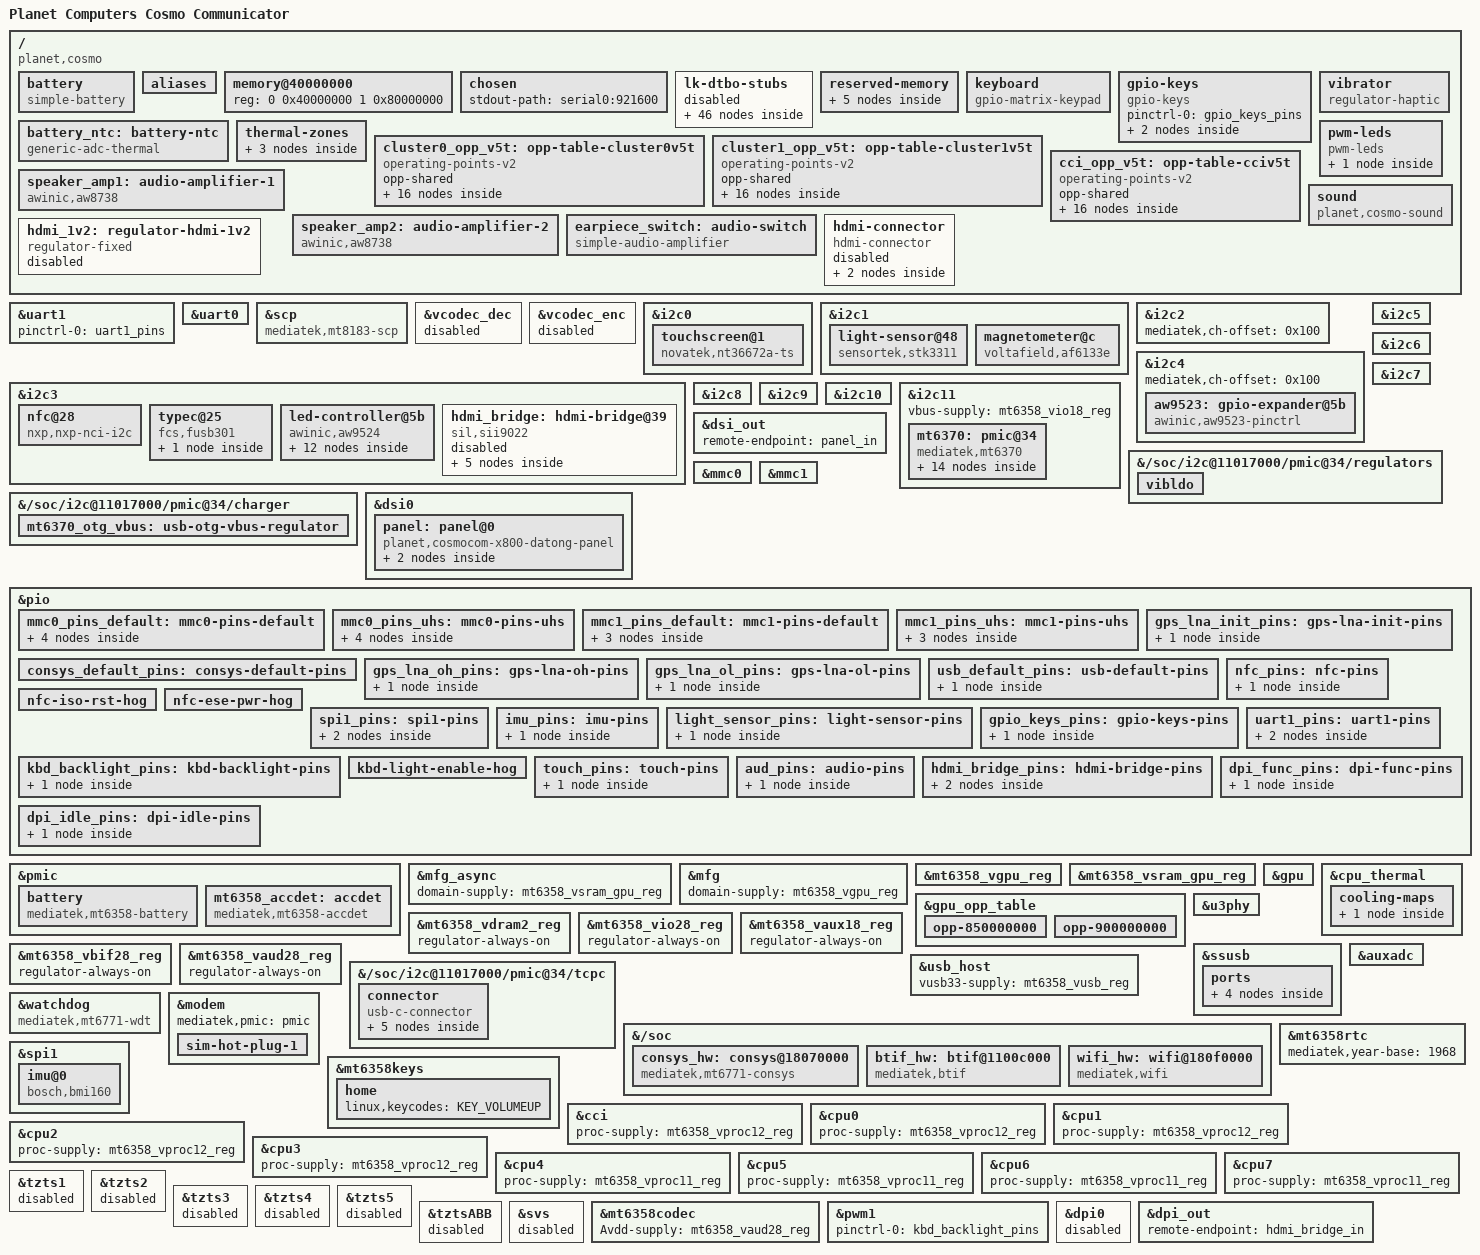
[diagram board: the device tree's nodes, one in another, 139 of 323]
// SPDX-License-Identifier: (GPL-2.0 OR MIT)
/*
 * Planet Computers Cosmo Communicator (board k71v1_64_bsp) on MediaTek MT6771.
 */

/dts-v1/;
#include <dt-bindings/gpio/gpio.h>
#include <dt-bindings/iio/adc/mediatek,mt6370_adc.h>
#include <dt-bindings/input/input.h>
#include <dt-bindings/interrupt-controller/irq.h>
#include <dt-bindings/power/mt8183-power.h>
#include <dt-bindings/clock/mt8183-clk.h>
#include <dt-bindings/leds/common.h>
#include <dt-bindings/usb/pd.h>
#include <dt-bindings/iio/adc/mediatek,mt6358-auxadc.h>
#include "mt6771.dtsi"
/* The MT6358 PMIC, so regulators exist at all. LK reports its chip code as 0x5820, which the vendor
 * kernel's mtk_pmic_info.h defines as PMIC6358_E2_CID_CODE. Otto Pflueger's tree includes it too. */
#include "mt6358.dtsi"

/*
 * Power features prepared but not yet tested on the phone; 0 keeps the tested configuration.
 * COSMO_CPU_OPP_V5T: 1 = this chip's V5_T CPU/CCI tables without L 2106 MHz, 2 = with it.
 * COSMO_SENSOR_ZONES: 1 = per-sensor thermal zones (soc, gpu, md1, cpu-little, cpu-big).
 * COSMO_SVS: 1 = mtk-svs; needs COSMO_CPU_OPP_V5T 2 (or 0) and COSMO_SENSOR_ZONES 1.
 * COSMO_CPUIDLE: 1 = PSCI core-off idle (vendor MCDI state), 2 = also cluster-off.
 * COSMO_VCODEC: 1 = SCP runs mediatek/mt8183/scp.img instead of the LK-loaded sensor hub, with VDEC/VENC.
 */
#define COSMO_CPU_OPP_V5T	0
#define COSMO_SENSOR_ZONES	0
#define COSMO_SVS		0
#define COSMO_CPUIDLE		0
#define COSMO_VCODEC		0

#if COSMO_SVS && (!COSMO_SENSOR_ZONES || COSMO_CPU_OPP_V5T == 1)
#error "COSMO_SVS needs the gpu-thermal zone and 16 OPPs per CPU bank"
#endif

/ {
	model = "Planet Computers Cosmo Communicator";
	chassis-type = "handset";
	compatible = "planet,cosmo", "mediatek,mt6771";

	/*
	 * The limits the vendor charges this battery with, from the phone's live device tree
	 * (mt6370 charger node: cv 4400000, ichg 2050000, ieoc 150000). The charger driver programs
	 * the voltage and the termination current and refuses to go above the maxima.
	 */
	/*
	 * Capacity and OCV curve: the vendor gauge profile at 25 C (bat_setting/mt6771_battery_table.dtsi
	 * battery0_profile_t1, MediaTek reference data), 4275.9 mAh down to its 3.40 V point. The
	 * resistance is that profile's third column read as 0.1 mOhm (unit not stated in the source).
	 */
	battery: battery {
		compatible = "simple-battery";
		device-chemistry = "lithium-ion-polymer";
		constant-charge-voltage-max-microvolt = <4400000>;
		constant-charge-current-max-microamp = <2050000>;
		charge-term-current-microamp = <150000>;
		charge-full-design-microamp-hours = <4275900>;
		voltage-min-design-microvolt = <3400000>;
		factory-internal-resistance-micro-ohms = <170000>;
		ocv-capacity-celsius = <25>;
		ocv-capacity-table-0 = <4364700 100>, <4307738 95>, <4250256 90>, <4193949 85>,
				       <4139577 80>, <4085567 75>, <4041958 70>, <3975215 65>,
				       <3942221 60>, <3888566 55>, <3854915 50>, <3829528 45>,
				       <3809099 40>, <3792341 35>, <3777940 30>, <3760049 25>,
				       <3741745 20>, <3717367 15>, <3689589 10>, <3677789 5>,
				       <3399901 0>;
	};

	aliases {
		serial0 = &uart0;
		serial1 = &uart1;
		/* The SD card probes first and took mmcblk0; root= names the eMMC as mmcblk0p43. */
		mmc0 = &mmc0;
		mmc1 = &mmc1;
	};

	memory@40000000 {
		device_type = "memory";
		/*
		 * 6 GiB from 0x40000000. Two independent sources: the device
		 * owner, and Otto Pflueger's mt6771-planet-cosmocom.dts:29
		 * (reg = <0 0x40000000 1 0x80000000>). The vendor's own size,
		 * 0x1e605000 (V:226), is a bring-up value that stops at the
		 * framebuffer base and is not used. The base is the vendor's.
		 * Not proven: that the range is contiguous, with no hole the
		 * firmware owns; only a boot settles that.
		 */
		reg = <0 0x40000000 1 0x80000000>;
	};

	chosen {
		/* 921600 from vendor mt6771.dts:32 (console=ttyS0,921600n1) */
		stdout-path = "serial0:921600";
		#address-cells = <2>;
		#size-cells = <2>;
		ranges;

		/*
		 * NO simple-framebuffer here, and the reason is worth keeping.
		 *
		 * We derived a handover framebuffer at 0x5e605000 from chosen/atag,videolfb-fb_base_l and
		 * reserved it. LK rejected the whole device tree for it:
		 *
		 *   reserved_memory_conflict_check fatal error keep while (1)
		 *
		 * then spun until the watchdog. Its own log says why: free memory resumes at 0x5e900000, and
		 * 0x56900000-0x5e900000 is LK's scratch_addr_mb -- the buffer it decompresses the kernel into.
		 * 0x5e605000 is inside it. That address is LK's workspace, not a framebuffer it hands over.
		 *
		 * The live device tree's real display reservation is mblock-7-framebuffer at 0x7df70000, which
		 * is reserved below and is the address Otto Pflueger's tree uses -- commented out there too.
		 * If a screen console is wanted later, that is where to start, and its geometry needs proving
		 * against a boot rather than against an atag.
		 */
	};

	/*
	 * Targets for the vendor device-tree overlay. Not hardware.
	 *
	 * MediaTek's LK applies the overlay in the device's dtbo partition to whatever tree it finds in the
	 * boot image, and it is not optional: when a fixup cannot be resolved it does not fall back, it
	 * asserts, and the kernel never runs. Read out of expdb after a silent boot:
	 *
	 *   ERROR: ufdt_overlay_do_fixups():No node __symbols__ in main dtb.
	 *   ufdt_apply_overlay() failed!
	 *   panic (caller 0x5602c2d3): ASSERT at (app/mt_boot/fdt_op.c:212): 0
	 *
	 * The overlay names 61 symbols. Inheriting mt8183.dtsi supplies 18 of them; these
	 * 43 are vendor board labels with no mainline equivalent. They exist so the overlay
	 * resolves and LK proceeds, and they are deliberately empty and disabled so that whatever the overlay
	 * writes into them binds to nothing. Pointing them at real nodes would let 280 fragments of downstream
	 * properties into hardware we do describe.
	 *
	 * ci/check-dtbo-symbols.py reads the requirement out of the real dtbo partition, so this list cannot
	 * drift from the device without the build failing.
	 */
	lk-dtbo-stubs {
		status = "disabled";

		/*
		 * Targets for the overlay's i2c1, i2c3 and spi1 fragments: ci/mkbootimg-cosmo.py points
		 * those symbols here, so the vendor's placeholder clients stay off our buses. Each carries
		 * a status so the packer can check the node exists.
		 */
		i2c1_lkstub: i2c1-stub { status = "disabled"; #address-cells = <1>; #size-cells = <0>; };
		i2c3_lkstub: i2c3-stub { status = "disabled"; #address-cells = <1>; #size-cells = <0>; };
		spi1_lkstub: spi1-stub { status = "disabled"; #address-cells = <1>; #size-cells = <0>; };

		accdet: accdet-stub { };
		als: als-stub { };
		apuart0: apuart0-stub { };
		audgpio: audgpio-stub { };
		aw9523_eint: aw9523-eint-stub { };
		aw9523_key: aw9523-key-stub { };
		aw9524_key: aw9524-key-stub { };
		charger: charger-stub { };
		chosen: chosen-stub { };
		consys: consys-stub { };
		cs_finger: cs-finger-stub { };
		dsi_te: dsi-te-stub { };
		finger: finger-stub { };
		finger_key: finger-key-stub { };
		fusb301a: fusb301a-stub { };
		gpio: gpio-stub { };
		gpio_usage_mapping: gpio-usage-mapping-stub { };
		gyro: gyro-stub { };
		hall: hall-stub { };
		irq_nfc: irq-nfc-stub { };
		irtx_pwm: irtx-pwm-stub { };
		kd_camera_hw1: kd-camera-hw1-stub { };
		keypad: keypad-stub { };
		main_pmic: main-pmic-stub { };
		md1_sim1_hot_plug_eint: md1-sim1-hot-plug-eint-stub { };
		msdc1_ins: msdc1-ins-stub { };
		mt6370_pmu: mt6370-pmu-stub { };
		mt6370_typec: mt6370-typec-stub { };
		mt_pmic_vcama1_ldo_reg: mt-pmic-vcama1-ldo-reg-stub { };
		mt_pmic_vcama2_ldo_reg: mt-pmic-vcama2-ldo-reg-stub { };
		mt_pmic_vcamd_ldo_reg: mt-pmic-vcamd-ldo-reg-stub { };
		mt_pmic_vcamio_ldo_reg: mt-pmic-vcamio-ldo-reg-stub { };
		mt_pmic_vldo28_ldo_reg: mt-pmic-vldo28-ldo-reg-stub { };
		mt_pmic_vsim1_ldo_reg: mt-pmic-vsim1-ldo-reg-stub { };
		mt_pmic_vsim2_ldo_reg: mt-pmic-vsim2-ldo-reg-stub { };
		odm: odm-stub { };
		pmic_clock_buffer_ctrl: pmic-clock-buffer-ctrl-stub { };
		reserved_memory: reserved-memory-stub { };
		sii9022: sii9022-stub { };
		stm32_key: stm32-key-stub { };
		subpmic_pmu_eint: subpmic-pmu-eint-stub { };
		tcpc_pd: tcpc-pd-stub { };
		touch: touch-stub { };
	};

	reserved-memory {
		#address-cells = <2>;
		#size-cells = <2>;
		ranges;

		/*
		 * Only what LK does NOT reserve itself.
		 *
		 * The firmware regions this file used to declare -- atf, spm, sspm, tee, log_store, framebuffer,
		 * three ccci, scp, vpu, the dramc ranks -- were transcribed from the live device tree of the
		 * running vendor kernel. That was a mistake in reasoning: the live tree is what the kernel
		 * receives AFTER LK has injected its own reservations, not what the vendor's source declares.
		 * Declaring them again collides with the originals, and LK refuses the tree outright:
		 *
		 *   DTS node:atf@54600000 reserved start: 0x54600000 size: 0x40000
		 *   reserved_memory_conflict_check:1168 failed i:3 0:1:1:1
		 *   reserved_memory_conflict_check fatal error keep while (1)
		 *
		 * atf@54600000 is byte-identical to LK's own atf-reserved. The three nodes that passed the check
		 * -- ramoops, ram-console, minirdump -- are precisely the ones LK does not inject.
		 *
		 * So the firmware regions still reach the kernel; they arrive from the bootloader, which is how
		 * the vendor kernel gets them too. Dynamic reservations (no fixed reg) are fine: they cannot
		 * collide, and LK looks reserve-memory-sspm_share up by name.
		 */

		/*
		 * The vendor pstore (V:298-301). Mainline ramoops takes the
		 * place of the vendor's own pstore. Sizes are the vendor's:
		 * console/pmsg from k71v1_64_bsp_defconfig:496-497, and the
		 * 4096-byte record size is the vendor ram.c default (ram.c:41).
		 * No no-map: it has to be mapped to be read back.
		 */
		ramoops@54410000 {
			compatible = "ramoops";
			reg = <0 0x54410000 0 0xe0000>;
			record-size = <0x1000>;
			/* Console last, 64 KiB, no pmsg: that puts it at 0x544e0000, the one part of this
			 * region the vendor kernel has read our writes back from every time (11-console-zone). */
			console-size = <0x10000>;
		};

		/* Vendor ram_console (V:302-305) and minirdump (V:306-309). */
		ram-console@54400000 {
			reg = <0 0x54400000 0 0x10000>;
		};

		minirdump@544f0000 {
			reg = <0 0x544f0000 0 0x10000>;
		};

		/*
		 * Regions the firmware owns, at the addresses it chose for
		 * this boot, from the live device tree the bootloader hands
		 * the vendor kernel (notes: probes/2026-09-24-1702-live.dts,
		 * reserved-memory node; line numbers below are that file's).
		 * The vendor source only declares most of these dynamically.
		 * Not reserving them lets the page allocator hand ATF, TEE or
		 * modem memory to the kernel. All no-map except where noted.
		 *
		 * The addresses are as observed on one boot. If LK places them
		 * differently on another boot these are wrong; see the notes.
		 */

		/* live:6017 mblock-10-SCP-reserved */
		/*
		 * live:5942 reserve-memory-sspm_share. LK looks this up by literal path,
		 * "/reserved-memory/reserve-memory-sspm_share", and writes "okay" into its status property --
		 * which is why the live tree shows status = <0x6f6b6179>, "okay" as a u32. Without the node LK
		 * logs "SSPM: no reserved mem found, skip" and shortly afterwards asserts. Values are the
		 * device's, not invented: a dynamic reservation rather than a fixed one.
		 */
		reserve-memory-sspm_share {
			compatible = "mediatek,reserve-memory-sspm_share";
			size = <0 0x510000>;
			alloc-ranges = <0 0x40000000 0 0x60000000>;
			alignment = <0 0x10000>;
			no-map;
		};

		/*
		 * The three pools below are placed by the kernel at boot from
		 * size, alignment and alloc-ranges (as in the vendor), not at a
		 * fixed address, and nothing consumes them until the SSPM, SCP
		 * and connsys drivers exist.
		 */

		/* V:331-337 */
		consys {
			compatible = "mediatek,consys-reserve-memory";
			no-map;
			size = <0 0x200000>;
			alignment = <0 0x200000>;
			alloc-ranges = <0 0x40000000 0 0x80000000>;
		};

#if COSMO_VCODEC
		/*
		 * Fixed address: scp.img links its DRAM segment at physical 0x50000000. Size as every mt8183
		 * board. Not in LK's mblock list, so its conflict check passes.
		 */
		scp_mem_reserved: memory@50000000 {
			compatible = "shared-dma-pool";
			reg = <0 0x50000000 0 0x2900000>;
			no-map;
		};
#endif
	};

};

/* Cover display: the STM32 speaks the CoDi protocol at 115200 baud (codi-app SerialPortManager.py) */
&uart1 {
	pinctrl-names = "default";
	pinctrl-0 = <&uart1_pins>;
	status = "okay";
};

&uart0 {
	status = "okay";
};

/*
 * LK finds the SCP node by the vendor compatible "mediatek,scp" and reads its sram size from reg[0].
 * Without it: "[SCP] platform_fdt_scp: getting node from dtb fails". mt8183.dtsi's node already carries
 * the right reg -- sram at 0x10500000 size 0x80000, identical to the vendor tree (live:7006) -- so all
 * it needs is the name the bootloader looks for. Without COSMO_VCODEC the node stays disabled.
 */
&scp {
	compatible = "mediatek,mt8183-scp", "mediatek,scp";

#if COSMO_VCODEC
	/*
	 * Same CM4 SCP as MT8183: IPC, reset, clock-control and cache registers at the same offsets
	 * (vendor scp/mt6771/scp_reg.h). mtk_scp boots it at probe, replacing LK's sensor hub image.
	 */
	firmware-name = "mediatek/mt8183/scp.img";
	status = "okay";
#else
	/*
	 * LK reserves its own SCP image region (SCP-reserved at 0x9cf00000, in its own
	 * mblock_reserve list) and rejects the whole device tree if we declare it a second time. So drop
	 * mt8183.dtsi's reference rather than duplicate LK's region. With COSMO_VCODEC it points at the
	 * separate pool scp.img needs instead.
	 */
	/delete-property/ memory-region;
#endif
};

#if !COSMO_VCODEC
/* Both are driven through the SCP firmware and cannot probe without it. */
&vcodec_dec {
	status = "disabled";
};

&vcodec_enc {
	status = "disabled";
};
#endif

/*
 * The MT6370 sub-PMIC, for the panel's bias rails (DSV) and backlight (WLED).
 *
 * The vendor calls this bus i2c-5, but that is its own numbering: the live tree's i2c5 alias points
 * at i2c@11017000 (id = <5>), which is the controller mt8183.dtsi labels i2c11. The vendor node has
 * no pinctrl either, so the pins are left as the bootloader muxed them. No clock-frequency: the
 * vendor runs this bus at 3.4 MHz high-speed, the controller's 100 kHz default is enough for a PMIC
 * and cannot be wrong for the wiring.
 */
/*
 * I2C on MT6771 vs the inherited MT8183 description (vendor mt6771.dts, dtbo fragment@40):
 * - the vendor's clk_src_div = 5 is a value it programs into the CLOCK_DIV register, not a fixed
 *   divider: mainline's clock-div means the opposite (already divided), and setting it to 5 ran the
 *   buses five times too fast. The inherited clock-div = <1> lets the driver pick the divider;
 * - i2c2 and i2c4 (the camera buses, shared with the CCU) are multi-channel controllers and the AP
 *   channel's registers start at +0x100 (vendor ch_offset_default, here mediatek,ch-offset), the
 *   arbitration/shadow registers stay at the base and the DMA channel at +0;
 * - the Cosmo keyboard is an AW9523B expander at 0x5b on i2c4 (8x7 matrix on P0/P1, RSTN on
 *   GPIO175, INTN on GPIO12), which nothing else declares: LK drives it for its boot menu.
 * Controllers without known clients are left on for now so peripherals can be located from Linux.
 */
&i2c0 {
	status = "okay";

	/*
	 * Novatek NT36672 TDDI touch (vendor cap_touch@62, NT36xxx driver). Firmware data sits at
	 * address 0x01; the parameter block reads 1080x2160, 10 touches, rising IRQ, chip id 0x08.
	 */
	touchscreen@1 {
		compatible = "novatek,nt36672a-ts";
		reg = <0x01>;
		interrupts-extended = <&pio 9 IRQ_TYPE_EDGE_RISING>;
		reset-gpios = <&pio 156 GPIO_ACTIVE_LOW>;
		pinctrl-names = "default";
		pinctrl-0 = <&touch_pins>;
	};
};
&i2c1 {
	status = "okay";

	/*
	 * Ambient light and proximity (vendor alsps@48, stk3x1x). The ID register reads 0x12, an
	 * STK3311 variant the stk3310 driver knows.
	 */
	light-sensor@48 {
		compatible = "sensortek,stk3311";
		reg = <0x48>;
		interrupts-extended = <&pio 6 IRQ_TYPE_LEVEL_LOW>;
		pinctrl-names = "default";
		pinctrl-0 = <&light_sensor_pins>;
	};

	/* Vendor msensor@0c, direction 2: x and y inverted; to be proven with a compass */
	magnetometer@c {
		compatible = "voltafield,af6133e";
		reg = <0x0c>;
		mount-matrix = "-1", "0", "0",
			       "0", "-1", "0",
			       "0", "0", "1";
	};
};
&i2c2 {
	mediatek,ch-offset = <0x100>;
	status = "okay";
};
&i2c3 {
	status = "okay";

	/*
	 * NXP PN553 (vendor nfc@28, libnfc-nxp.conf DEVICE_MODEL=PN553), own crystal. IRQ GPIO71
	 * level high as the vendor requests it, VEN GPIO72, firmware download GPIO73.
	 */
	nfc@28 {
		compatible = "nxp,nxp-nci-i2c";
		reg = <0x28>;
		interrupts-extended = <&pio 71 IRQ_TYPE_LEVEL_HIGH>;
		enable-gpios = <&pio 72 GPIO_ACTIVE_HIGH>;
		firmware-gpios = <&pio 73 GPIO_ACTIVE_HIGH>;
		pinctrl-names = "default";
		pinctrl-0 = <&nfc_pins>;
	};

	/*
	 * Cover LEDs (vendor aw9524_key.c /proc/aw9524_led_proc). function-enumerator is the vendor LED id
	 * codi-app uses: 1 tab, 2 right, 3 left, 7 fourth group. Current range 1/2 as the vendor sets
	 * (CTL 0x02); RSTN is GPIO109, left low (chip in reset) by the boot loader.
	 */
	/*
	 * Right USB-C port CC controller (vendor fusb301a@25, IRQ GPIO166). Sink only: the vendor
	 * never sources VBUS here and the OTG boost also feeds the left port. D+/D- stay on the
	 * left until the GPIO79 mux is modelled.
	 */
	typec@25 {
		compatible = "fcs,fusb301";
		reg = <0x25>;
		interrupts-extended = <&pio 166 IRQ_TYPE_LEVEL_LOW>;
		vbus-supply = <&mt6370_otg_vbus>;

		connector {
			compatible = "usb-c-connector";
			label = "USB-C right";
			power-role = "sink";
			data-role = "device";
			typec-power-opmode = "default";
			pd-disable;
		};
	};

	led-controller@5b {
		compatible = "awinic,aw9524";
		reg = <0x5b>;
		reset-gpios = <&pio 109 GPIO_ACTIVE_LOW>;
		awinic,led-max-microamp = <18500>;
		#address-cells = <1>;
		#size-cells = <0>;

		led@0 {
			reg = <0>;
			color = <LED_COLOR_ID_RED>;
			function = LED_FUNCTION_INDICATOR;
			function-enumerator = <1>;
		};

		led@1 {
			reg = <1>;
			color = <LED_COLOR_ID_GREEN>;
			function = LED_FUNCTION_INDICATOR;
			function-enumerator = <1>;
		};

		led@2 {
			reg = <2>;
			color = <LED_COLOR_ID_BLUE>;
			function = LED_FUNCTION_INDICATOR;
			function-enumerator = <1>;
		};

		led@3 {
			reg = <3>;
			color = <LED_COLOR_ID_RED>;
			function = LED_FUNCTION_INDICATOR;
			function-enumerator = <7>;
		};

		led@4 {
			reg = <4>;
			color = <LED_COLOR_ID_GREEN>;
			function = LED_FUNCTION_INDICATOR;
			function-enumerator = <7>;
		};

		led@5 {
			reg = <5>;
			color = <LED_COLOR_ID_BLUE>;
			function = LED_FUNCTION_INDICATOR;
			function-enumerator = <7>;
		};

		led@8 {
			reg = <8>;
			color = <LED_COLOR_ID_RED>;
			function = LED_FUNCTION_INDICATOR;
			function-enumerator = <2>;
		};

		led@9 {
			reg = <9>;
			color = <LED_COLOR_ID_GREEN>;
			function = LED_FUNCTION_INDICATOR;
			function-enumerator = <2>;
		};

		led@a {
			reg = <10>;
			color = <LED_COLOR_ID_BLUE>;
			function = LED_FUNCTION_INDICATOR;
			function-enumerator = <2>;
		};

		led@b {
			reg = <11>;
			color = <LED_COLOR_ID_RED>;
			function = LED_FUNCTION_INDICATOR;
			function-enumerator = <3>;
		};

		led@c {
			reg = <12>;
			color = <LED_COLOR_ID_GREEN>;
			function = LED_FUNCTION_INDICATOR;
			function-enumerator = <3>;
		};

		led@d {
			reg = <13>;
			color = <LED_COLOR_ID_BLUE>;
			function = LED_FUNCTION_INDICATOR;
			function-enumerator = <3>;
		};
	};
};
&i2c4 {
	mediatek,ch-offset = <0x100>;
	status = "okay";

	aw9523: gpio-expander@5b {
		compatible = "awinic,aw9523-pinctrl";
		reg = <0x5b>;
		interrupt-parent = <&pio>;
		interrupts = <12 IRQ_TYPE_EDGE_FALLING>;
		gpio-controller;
		#gpio-cells = <2>;
		gpio-ranges = <&aw9523 0 0 16>;
		interrupt-controller;
		#interrupt-cells = <2>;
		/*
		 * RSTN: LK leaves it low. The driver drives the line 0 then 1 and expects 1 to be
		 * "running" (its binding example uses GPIO_ACTIVE_HIGH), so no inversion here.
		 */
		reset-gpios = <&pio 175 GPIO_ACTIVE_HIGH>;
	};
};
&i2c5 { status = "okay"; };
&i2c6 { status = "okay"; };
&i2c7 { status = "okay"; };
&i2c8 { status = "okay"; };
&i2c9 { status = "okay"; };
&i2c10 { status = "okay"; };

&i2c11 {
	/* On: the MT6370 lives here, and its OTG boost is the only 5 V for USB host mode. */
	status = "okay";
	/*
	 * The controller driver asks for an optional "vbus" (bus pull-up) regulator. With none on this node,
	 * the regulator core's of_get_child_regulator() walks the bus's descendants and finds the Type-C
	 * connector's vbus-supply -- the MT6370 OTG boost, provided by a chip on this very bus -- and the
	 * controller waits for it forever ("deferred probe pending: cannot get vbus regulator"). Name the
	 * pull-up rail explicitly so the walk never runs. STAND-IN: VIO18 is the plausible 1.8 V I/O rail
	 * for these pull-ups; the schematic is not available.
	 */
	vbus-supply = <&mt6358_vio18_reg>;
	/*
	 * STAND-IN for the panel branch's status = "okay": here the bus stays "disabled", as mt8183.dtsi has
	 * it, so nothing on it probes before root mounts. Enabled per flash. Everything else in this block
	 * is byte-identical to dev/panel-nt36672 so the two merge without a conflict.
	 */

	/*
	 * Label deliberately not mt6370_pmu: that name belongs to the empty LK overlay stub above,
	 * which must stay a stub so the vendor overlay's properties bind to nothing.
	 */
	mt6370: pmic@34 {
		compatible = "mediatek,mt6370";
		reg = <0x34>;
		/*
		 * live tree mt6370_pmu_dts: mt6370,intr_gpio = <&pio 10 0>; gpio-330 is
		 * "mt6370_pmu_irq_gpio"
		 */
		interrupts-extended = <&pio 10 IRQ_TYPE_LEVEL_LOW>;
		interrupt-controller;
		#interrupt-cells = <1>;

		/*
		 * Only the backlight and the regulators are used. The binding wants every function
		 * described; the rest are disabled, which also keeps the MFD core from registering
		 * them, so nothing here reconfigures the charger or the USB-C port behind the
		 * vendor's back.
		 */
		mt6370_adc: adc {
			compatible = "mediatek,mt6370-adc";
			#io-channel-cells = <1>;
			status = "okay";
		};

		/*
		 * The panel's backlight: all four WLED strings (vendor mt,chan_en = <0xf>), with the
		 * vendor's protection settings (mt6370.dtsi: bl_ovp_level 3 = 29 V, bl_ocp_level 2 =
		 * 1500 mA, both shutting the boost down) and its linear brightness map.
		 *
		 * max-brightness is the vendor's mt,max_bled_brightness = <768> of the chip's 2047:
		 * Planet runs these LEDs at 37% of what the MT6370 can deliver, never more.
		 *
		 * No mediatek,bled-pwm-enable: the vendor dims with a PWM signal from the SoC
		 * (mt,use_pwm). Nothing on mainline drives that signal, the MT6370 kept following it,
		 * and the backlight flickered. Brightness is set over I2C alone here.
		 */
		mt6370_backlight: backlight {
			compatible = "mediatek,mt6370-backlight";
			mediatek,bled-channel-use = /bits/ 8 <15>;
			mediatek,bled-ovp-shutdown;
			mediatek,bled-ovp-microvolt = <29000000>;
			mediatek,bled-ocp-shutdown;
			mediatek,bled-ocp-microamp = <1500000>;
			max-brightness = <768>;
			default-brightness = <384>;
		};

		charger {
			compatible = "mediatek,mt6370-charger";
			interrupts = <68>, <48>, <6>;
			interrupt-names = "uvp_d_evt", "attach_i", "mivr";
			monitored-battery = <&battery>;
			/*
			 * All nine, in the binding's order: the driver indexes this list by channel
			 * number (IBUS is [5]). With IBUS alone it read past the end of a one-entry
			 * array whenever the MIVR interrupt fired, and the resulting oops in a kworker
			 * left the boot half dead (NetworkManager and polkit never started).
			 */
			io-channels = <&mt6370_adc MT6370_CHAN_VBUSDIV5>,
				      <&mt6370_adc MT6370_CHAN_VBUSDIV2>,
				      <&mt6370_adc MT6370_CHAN_VSYS>,
				      <&mt6370_adc MT6370_CHAN_VBAT>,
				      <&mt6370_adc MT6370_CHAN_TS_BAT>,
				      <&mt6370_adc MT6370_CHAN_IBUS>,
				      <&mt6370_adc MT6370_CHAN_IBAT>,
				      <&mt6370_adc MT6370_CHAN_CHG_VDDP>,
				      <&mt6370_adc MT6370_CHAN_TEMP_JC>;
			status = "okay";
		};

		/* Vendor mt6370_pmu_dts flash limits; the timeout is capped at the hardware 1.248 s */
		flashlight {
			compatible = "mediatek,mt6370-flashlight";
			#address-cells = <1>;
			#size-cells = <0>;

			led@0 {
				reg = <0>;
				led-sources = <0>;
				function = LED_FUNCTION_FLASH;
				color = <LED_COLOR_ID_WHITE>;
				function-enumerator = <1>;
				led-max-microamp = <300000>;
				flash-max-microamp = <1200000>;
				flash-max-timeout-us = <1248000>;
			};

			led@1 {
				reg = <1>;
				led-sources = <1>;
				function = LED_FUNCTION_FLASH;
				color = <LED_COLOR_ID_WHITE>;
				function-enumerator = <2>;
				led-max-microamp = <200000>;
				flash-max-microamp = <1000000>;
				flash-max-timeout-us = <1200000>;
			};
		};

		/*
		 * Vendor rgbled: ISINK1 green, ISINK2 blue, ISINK4 red (ISINK3 unused). Red is left out:
		 * undeclared, ISINK4 stays the MT6370's hardware charging indicator, also in suspend.
		 */
		indicator {
			compatible = "mediatek,mt6370-indicator";
			#address-cells = <1>;
			#size-cells = <0>;

			led@0 {
				reg = <0>;
				function = LED_FUNCTION_INDICATOR;
				color = <LED_COLOR_ID_GREEN>;
				led-max-microamp = <24000>;
			};

			led@1 {
				reg = <1>;
				function = LED_FUNCTION_INDICATOR;
				color = <LED_COLOR_ID_BLUE>;
				led-max-microamp = <24000>;
			};
		};

		/* live tree mt6370pd,intr_gpio = <&pio 41 0>; gpio-361 is "type_c_port0-IRQ" */
		mt6370_tcpc: tcpc {
			compatible = "mediatek,mt6370-tcpc";
			interrupts-extended = <&pio 41 IRQ_TYPE_LEVEL_LOW>;
			status = "okay";
		};

		/*
		 * Enabled over I2C (live tree dsv: db_ext_en = <0>), so no enable-gpios. Voltages
		 * are the vendor's: the boost from db_vbst = <0x1644> (5700 mV), the outputs from
		 * lcm_pmic.c:59,64 (5.4 V each, and regulator_summary on the running device
		 * agrees).
		 */
		regulators {
			dsvbst {
				regulator-name = "mt6370-dsv-vbst";
				regulator-min-microvolt = <5700000>;
				regulator-max-microvolt = <5700000>;
			};

			mt6370_dsvpos: dsvpos {
				/* Panel bias; nothing consumes it until the panel driver does. */
				regulator-always-on;
				regulator-name = "mt6370-dsv-vpos";
				regulator-min-microvolt = <5400000>;
				regulator-max-microvolt = <5400000>;
			};

			mt6370_dsvneg: dsvneg {
				/* Panel bias; nothing consumes it until the panel driver does. */
				regulator-always-on;
				regulator-name = "mt6370-dsv-vneg";
				regulator-min-microvolt = <5400000>;
				regulator-max-microvolt = <5400000>;
			};
		};
	};
};

/*
 * The rest of the MT6370, beyond what the panel needs. Written as references by path so this block and the
 * panel branch's node above stay byte-identical and merge cleanly. The indicator and flash LEDs are
 * described in the MT6370 node itself.
 *
 * live.dts:7171 mt6370_pmu_dts is the vendor node; the vendor's own driver is mt6370_pmu_*, which mainline
 * replaces with the mfd, charger, LED and regulator drivers.
 */
&{/soc/i2c@11017000/pmic@34/charger} {
	/*
	 * VBUS out for the Type-C connector. Otto Pflueger's node; the vendor drives OTG from the charger and
	 * the aeon_usb_otg_en pins (live.dts:7450), which mainline models as this regulator. Range is the
	 * MT6370's, not a measurement.
	 */
	mt6370_otg_vbus: usb-otg-vbus-regulator {
		regulator-name = "mt6370-usb-otg-vbus";
		/* The boost's own table (mt6370-charger: 4.425 V + n * 25 mV), as mt8195-demo writes it. */
		regulator-min-microvolt = <4425000>;
		regulator-max-microvolt = <5825000>;
		/* The vendor's OTG limit: 500 mA at enable, 1.5 A once host mode is up (xhci-mtk-driver.c). */
		regulator-min-microamp = <500000>;
		regulator-max-microamp = <1500000>;
	};
};

/*
 * live.dts:7226 mt6370_pmu_ldo, min 1.6 V, max 4.0 V. The vendor names the regulator "irtx_ldo": the
 * infrared transmitter's supply. Mainline calls the same block VIBLDO.
 */
&{/soc/i2c@11017000/pmic@34/regulators} {
	vibldo {
		regulator-name = "mt6370-vib-ldo";
		regulator-min-microvolt = <1600000>;
		regulator-max-microvolt = <4000000>;
	};
};

/*
 * The display, described rather than left to be discovered.
 *
 * mt8183.dtsi brings the whole display pipeline with it, so mtk_drm bound and started driving the panel
 * with no panel node, no endpoint graph and no supplies -- which is what put garbage on the screen and is
 * a plausible place to wedge. This is Otto Pflueger's description, minus the backlight: his points at the
 * MT6370 PMU on i2c, which we have not wired yet, and panel-simple treats backlight as optional. The
 * screen will stay dark; we read the log through pstore, not the screen.
 */
&dsi0 {
	status = "okay";
	#address-cells = <1>;
	#size-cells = <0>;

	panel: panel@0 {
		compatible = "planet,cosmocom-x800-datong-panel";
		reg = <0>;
		rotation = <270>;

		port {
			panel_in: endpoint {
				remote-endpoint = <&dsi_out>;
			};
		};
	};
};

/* mt8183.dtsi already declares dsi0's ports and labels its output endpoint, so wire that one up rather
 * than declaring a second. */
&dsi_out {
	remote-endpoint = <&panel_in>;
};

/*
 * eMMC and SD card. These two are the only nodes in this file that are meant to be live before root
 * mounts; everything else the board description adds is disabled and is switched on per flash.
 *
 * The vendor calls them msdc@11230000 and msdc@11240000 (live.dts:294, :320); mainline's mt8183-mmc
 * binding drives the same controllers. Capabilities, bus width and supplies are the vendor's.
 *
 * Drive strength is the VENDOR's, not Otto Pflueger's. The live tree's msdc pin groups
 * (live.dts:1212 msdc0@default, :1243 msdc1@default and its sdr104/sdr50/ddr50 twins) carry a register
 * field of 4 for msdc0 and 3 for msdc1, in 2 mA steps from 2 mA: 10 mA and 8 mA. Otto's tree, and the
 * mt8183 boards it was copied from, use 14 mA and 10 mA. The two disagree; the vendor's are what this
 * board ran with, so they are used here, and only a boot on this device can say whether they are enough
 * at HS400.
 *
 * The vendor groups set drive strength only: the pads are muxed by LK, and the pinmux and pull settings
 * below are the mt8183 boards' (the SoC's pad design is shared). STAND-IN: the pull-up/pull-down
 * settings, until measured against the vendor's msdc register dump. The *-adv properties take the
 * 2-bit register value as a number (0-3); mt8183-kukui writes them as <10> and <01>, which dtc reads as
 * decimal ten and (octal) one, and the schema rejects the ten. <2> is the binary 10 those boards mean.
 */
&mmc0 {
	status = "okay";
	pinctrl-names = "default", "state_uhs";
	pinctrl-0 = <&mmc0_pins_default>;
	pinctrl-1 = <&mmc0_pins_uhs>;
	bus-width = <8>;
	max-frequency = <200000000>;
	cap-mmc-highspeed;
	mmc-ddr-1_8v;
	mmc-hs200-1_8v;
	mmc-hs400-1_8v;
	cap-mmc-hw-reset;
	no-sdio;
	no-sd;
	/*
	 * STAND-IN: the mt8183 HS400 data-strobe delay (mt8183-kukui and Otto's tree both carry it). The
	 * vendor has no such property; its tuning is done in the driver at run time. Replace with the value
	 * the eMMC tuning settles on.
	 */
	hs400-ds-delay = <0x12814>;
	non-removable;
	/*
	 * live.dts:317 vmmc-supply is the only supply the vendor gives msdc0. The mt8183-mmc binding
	 * requires a vqmmc-supply as well, so VIO18 goes there as in Otto's tree. STAND-IN: that choice has no
	 * vendor basis (nothing in live.dts consumes VIO18); it is the always-on 1.8 V I/O rail (mt6358.dtsi)
	 * the eMMC's I/O most plausibly sits on. WAITING: the board schematic.
	 */
	vmmc-supply = <&mt6358_vemc_reg>;
	vqmmc-supply = <&mt6358_vio18_reg>;
};

&mmc1 {
	status = "okay";
	pinctrl-names = "default", "state_uhs";
	pinctrl-0 = <&mmc1_pins_default>;
	pinctrl-1 = <&mmc1_pins_uhs>;
	bus-width = <4>;
	max-frequency = <200000000>;
	cap-sd-highspeed;
	sd-uhs-sdr12;
	sd-uhs-sdr25;
	sd-uhs-sdr50;
	sd-uhs-sdr104;
	sd-uhs-ddr50;
	/*
	 * live.dts:332 cd-gpios = <&pio 3 0>, cd_level = 1. The vendor's sd.c:4511 sets
	 * card_inserted = (cd_level == level), so the card is present when the pin is HIGH: active high, the
	 * opposite of most boards. gpio.txt shows gpio-323 (base 320 + pin 3) "in hi" with the pin claimed
	 * by "cd". WAITING: confirm with a card in and out.
	 */
	cd-gpios = <&pio 3 GPIO_ACTIVE_HIGH>;
	vmmc-supply = <&mt6358_vmch_reg>;
	vqmmc-supply = <&mt6358_vmc_reg>;
};

&pio {
	mmc0_pins_default: mmc0-pins-default {
		pins-cmd-dat {
			pinmux = <PINMUX_GPIO123__FUNC_MSDC0_DAT0>,
				 <PINMUX_GPIO128__FUNC_MSDC0_DAT1>,
				 <PINMUX_GPIO125__FUNC_MSDC0_DAT2>,
				 <PINMUX_GPIO132__FUNC_MSDC0_DAT3>,
				 <PINMUX_GPIO126__FUNC_MSDC0_DAT4>,
				 <PINMUX_GPIO129__FUNC_MSDC0_DAT5>,
				 <PINMUX_GPIO127__FUNC_MSDC0_DAT6>,
				 <PINMUX_GPIO130__FUNC_MSDC0_DAT7>,
				 <PINMUX_GPIO122__FUNC_MSDC0_CMD>;
			input-enable;
			drive-strength = <MTK_DRIVE_10mA>;
			mediatek,pull-up-adv = <1>;
		};

		pins-clk {
			pinmux = <PINMUX_GPIO124__FUNC_MSDC0_CLK>;
			drive-strength = <MTK_DRIVE_10mA>;
			mediatek,pull-down-adv = <2>;
		};

		pins-ds {
			pinmux = <PINMUX_GPIO131__FUNC_MSDC0_DSL>;
			drive-strength = <MTK_DRIVE_10mA>;
			mediatek,pull-down-adv = <2>;
		};

		pins-rst {
			pinmux = <PINMUX_GPIO133__FUNC_MSDC0_RSTB>;
			drive-strength = <MTK_DRIVE_10mA>;
			mediatek,pull-down-adv = <1>;
		};
	};

	/* The vendor has one msdc0 state (live.dts:1212); the UHS state repeats it. */
	mmc0_pins_uhs: mmc0-pins-uhs {
		pins-cmd-dat {
			pinmux = <PINMUX_GPIO123__FUNC_MSDC0_DAT0>,
				 <PINMUX_GPIO128__FUNC_MSDC0_DAT1>,
				 <PINMUX_GPIO125__FUNC_MSDC0_DAT2>,
				 <PINMUX_GPIO132__FUNC_MSDC0_DAT3>,
				 <PINMUX_GPIO126__FUNC_MSDC0_DAT4>,
				 <PINMUX_GPIO129__FUNC_MSDC0_DAT5>,
				 <PINMUX_GPIO127__FUNC_MSDC0_DAT6>,
				 <PINMUX_GPIO130__FUNC_MSDC0_DAT7>,
				 <PINMUX_GPIO122__FUNC_MSDC0_CMD>;
			input-enable;
			drive-strength = <MTK_DRIVE_10mA>;
			mediatek,pull-up-adv = <1>;
		};

		pins-clk {
			pinmux = <PINMUX_GPIO124__FUNC_MSDC0_CLK>;
			drive-strength = <MTK_DRIVE_10mA>;
			mediatek,pull-down-adv = <2>;
		};

		pins-ds {
			pinmux = <PINMUX_GPIO131__FUNC_MSDC0_DSL>;
			drive-strength = <MTK_DRIVE_10mA>;
			mediatek,pull-down-adv = <2>;
		};

		pins-rst {
			pinmux = <PINMUX_GPIO133__FUNC_MSDC0_RSTB>;
			drive-strength = <MTK_DRIVE_10mA>;
			mediatek,pull-down-adv = <1>;
		};
	};

	/* live.dts:1243; sdr104, sdr50 and ddr50 (:1259-:1291) are identical, so one state serves. */
	mmc1_pins_default: mmc1-pins-default {
		pins-cmd-dat {
			pinmux = <PINMUX_GPIO31__FUNC_MSDC1_CMD>,
				 <PINMUX_GPIO32__FUNC_MSDC1_DAT0>,
				 <PINMUX_GPIO34__FUNC_MSDC1_DAT1>,
				 <PINMUX_GPIO33__FUNC_MSDC1_DAT2>,
				 <PINMUX_GPIO30__FUNC_MSDC1_DAT3>;
			input-enable;
			drive-strength = <MTK_DRIVE_8mA>;
			mediatek,pull-up-adv = <2>;
		};

		pins-clk {
			pinmux = <PINMUX_GPIO29__FUNC_MSDC1_CLK>;
			input-enable;
			drive-strength = <MTK_DRIVE_8mA>;
			mediatek,pull-down-adv = <2>;
		};

		pins-cd {
			pinmux = <PINMUX_GPIO3__FUNC_GPIO3>;
			input-enable;
			bias-pull-up;
		};
	};

	mmc1_pins_uhs: mmc1-pins-uhs {
		pins-cmd-dat {
			pinmux = <PINMUX_GPIO31__FUNC_MSDC1_CMD>,
				 <PINMUX_GPIO32__FUNC_MSDC1_DAT0>,
				 <PINMUX_GPIO34__FUNC_MSDC1_DAT1>,
				 <PINMUX_GPIO33__FUNC_MSDC1_DAT2>,
				 <PINMUX_GPIO30__FUNC_MSDC1_DAT3>;
			input-enable;
			drive-strength = <MTK_DRIVE_8mA>;
			mediatek,pull-up-adv = <2>;
		};

		pins-clk {
			pinmux = <PINMUX_GPIO29__FUNC_MSDC1_CLK>;
			input-enable;
			drive-strength = <MTK_DRIVE_8mA>;
			mediatek,pull-down-adv = <2>;
		};

		pins-cd {
			pinmux = <PINMUX_GPIO3__FUNC_GPIO3>;
			input-enable;
			bias-pull-up;
		};
	};
};

/*
 * The MT6358's interrupt line: pin 182, the vendor's "pmic-eint" (interrupts.txt in the runtime
 * snapshot: mtk-eint 182 Level pmic-eint). Without it the mt6397 MFD core fails to probe
 * ("pmic: IRQ index 0 not found", first console log), and every MT6358 regulator, the MFG power
 * domain and the eMMC's supplies go with it. Same pin as mt8183-kukui.
 */
&pmic {
	interrupts-extended = <&pio 182 IRQ_TYPE_LEVEL_HIGH>;
};

/*
 * The MFG power domains need their rails or the whole power controller fails to probe
 * ("power-domain@2: failed to get power supply", console log 2026-09-25), which leaves every
 * display block and the GPU waiting for it forever. Same rails as mt8183-kukui; the vendor's GPU
 * DVFS log confirms VGPU and VSRAM_GPU (vendor-boot.log: "VGPU is enabled = 1 (900 mV), VSRAM_GPU
 * is enabled = 1 (1000 mV)").
 */
&mfg_async {
	domain-supply = <&mt6358_vsram_gpu_reg>;
};

&mfg {
	domain-supply = <&mt6358_vgpu_reg>;
};

/* Vendor GPU rails: Vgpu at most 900 mV, Vsram = max(850, Vgpu + 100) capped at 1000 mV */
&mt6358_vgpu_reg {
	regulator-max-microvolt = <900000>;
	regulator-coupled-with = <&mt6358_vsram_gpu_reg>;
	regulator-coupled-max-spread = <100000>;
};

&mt6358_vsram_gpu_reg {
	regulator-min-microvolt = <850000>;
	regulator-max-microvolt = <1000000>;
	regulator-coupled-with = <&mt6358_vgpu_reg>;
	regulator-coupled-max-spread = <100000>;
};

&gpu {
	mali-supply = <&mt6358_vgpu_reg>;
	#cooling-cells = <2>;
	/* vendor GPU_ACT_REF_POWER 1285 mW at 900 MHz, 0.90 V (mtk_gpufreq_core.h:276-278) */
	dynamic-power-coefficient = <1763>;
};

/*
 * The vendor thermal policy budgets CPU and GPU power together; add the GPU to the SoC zone. The
 * vendor keeps at least 250 mW for the GPU (thermal.conf clatm min GPU): state 15 is 340 MHz, about
 * 243 mW with the power model above, so throttling stops there (state 13 in the 16-OPP SVS table).
 */
&cpu_thermal {
	cooling-maps {
		map2 {
			trip = <&target>;
#if COSMO_SVS
			cooling-device = <&gpu THERMAL_NO_LIMIT 13>;
#else
			cooling-device = <&gpu THERMAL_NO_LIMIT 15>;
#endif
			contribution = <1024>;
		};
	};
};

/* Vendor speed segment 4 (efuse speed bound 2 with turbo) runs the GPU up to 900 MHz */
&gpu_opp_table {
	opp-850000000 {
		opp-hz = /bits/ 64 <850000000>;
		opp-microvolt = <862500>;
	};

	opp-900000000 {
		opp-hz = /bits/ 64 <900000000>;
		opp-microvolt = <900000>;
	};

#if COSMO_SVS
	/* the SVS GPU bank needs exactly 16 OPPs; segment 4 has neither of these (mtk_gpufreq_core.h:182-231) */
	/delete-node/ opp-360000000;
	/delete-node/ opp-400000000;
#endif
};

/*
 * Rails the vendor keeps up that nothing in this tree consumes yet. Thirty seconds after boot the
 * regulator core switched them off (console log 2026-09-25: "vdram2: disabling" was the last line
 * before the reset) -- VDRAM2 feeds the DRAM. mt8183-kukui marks vdram2 always-on for the same reason.
 */
&mt6358_vdram2_reg {
	regulator-always-on;
};

&mt6358_vio28_reg {
	regulator-always-on;
};

&mt6358_vaux18_reg {
	regulator-always-on;
};

&mt6358_vbif28_reg {
	regulator-always-on;
};

&mt6358_vaud28_reg {
	regulator-always-on;
};

/*
 * USB. The vendor's usb3@11200000 (live.dts:4160, mediatek,usb3) is mainline's mtu3 at 11201000 with the
 * xhci child at 11200000, and its PHY (live.dts:6164 usb3_phy) is phy-mtk-tphy at 11f40000. Both are
 * mt8183.dtsi's nodes; the SoC block is the same one.
 *
 * All of it stays disabled. Type-C is on the MT6370's TCPC at i2c 0x4e (live.dts:3023 usb_type_c@4e), not
 * on the FUSB301A at i2c-3 0x25: that one is the right port's CC controller, whose orientation the
 * vendor uses to steer the HDMI lane switch (pins 176 and 177, aeon_fusb301a_sw_sel/sw_en, live.dts:7454;
 * see the HDMI block at the end). The TCPC has no separate i2c client in the mainline binding; it is the
 * tcpc child of the MT6370 node.
 */
&u3phy {
	/* on in mt8183.dtsi; nothing may power the PHY until the port above it is described and enabled */
	status = "okay";
};

&ssusb {
	/*
	 * Dual role under the MT6370's Type-C port controller, as the vendor runs it: TCPM presents Rp,
	 * sees the attach, sources VBUS through the connector's vbus-supply and switches this controller
	 * to host. Plain host mode with VBUS forced on got no attach from a PD-aware hub.
	 */
	pinctrl-names = "default";
	pinctrl-0 = <&usb_default_pins>;	/* GPIO79 low: D+/D- to the left (MT6370) port */
	vusb33-supply = <&mt6358_vusb_reg>;
	dr_mode = "otg";
	usb-role-switch;
	role-switch-default-mode = "peripheral";
	/* USB3 off: the SuperSpeed lane goes through the FUSB301A mux, which nothing drives yet. */
	mediatek,u3p-dis-msk = <1>;
	status = "okay";

	ports {
		#address-cells = <1>;
		#size-cells = <0>;

		port@0 {
			reg = <0>;

			ssusb_hs_ep: endpoint {
				remote-endpoint = <&tcpc_hs_ep>;
			};
		};

		port@1 {
			reg = <1>;

			ssusb_ss_ep: endpoint {
				remote-endpoint = <&tcpc_ss_ep>;
			};
		};
	};
};

&usb_host {
	vusb33-supply = <&mt6358_vusb_reg>;
	status = "okay";
};


&pio {
	consys_default_pins: consys-default-pins {
	};

	gps_lna_init_pins: gps-lna-init-pins {
		pins-cmd-dat {
			pinmux = <PINMUX_GPIO155__FUNC_GPIO155>;
			bias-disable;
			output-low;
		};
	};

	gps_lna_oh_pins: gps-lna-oh-pins {
		pins-cmd-dat {
			pinmux = <PINMUX_GPIO155__FUNC_GPIO155>;
			output-high;
		};
	};

	gps_lna_ol_pins: gps-lna-ol-pins {
		pins-cmd-dat {
			pinmux = <PINMUX_GPIO155__FUNC_GPIO155>;
			output-low;
		};
	};

	/*
	 * live.dts:7464 aeon_usb_lr_sw_low/high (pin 79): the vendor switches the USB data lines between the
	 * two USB ports with this pin. Low is the left port in Otto's tree. WAITING: which level the
	 * vendor's default state is, and which port is which, are not in the live tree.
	 */
	usb_default_pins: usb-default-pins {
		pins-lr-switch {
			pinmux = <PINMUX_GPIO79__FUNC_GPIO79>;
			output-low;
		};
	};
};

/*
 * The connector on the left port (live.dts:7298 type_c_port0: role_def 4 = dual role). The MT6370's TCPC
 * is the port controller; its VBUS source is the charger's OTG boost. PDOs are STAND-INs at 5 V.
 */
&{/soc/i2c@11017000/pmic@34/tcpc} {
	connector {
		compatible = "usb-c-connector";
		label = "USB-C";
		vbus-supply = <&mt6370_otg_vbus>;
		data-role = "dual";
		power-role = "dual";
		/*
		 * No try-power-role: the vendor runs role_def 4 (plain DRP, tcpci_typec.c). With Try.SNK,
		 * TCPM drops Rp for tDRPTry after every attach, which a hub with its own PD controller sees
		 * as a detach.
		 */
		source-pdos = <PDO_FIXED(5000, 500, PDO_FIXED_DUAL_ROLE | PDO_FIXED_DATA_SWAP)>;
		sink-pdos = <PDO_FIXED(5000, 2000, PDO_FIXED_DUAL_ROLE | PDO_FIXED_DATA_SWAP)>;
		op-sink-microwatt = <10000000>;

		ports {
			#address-cells = <1>;
			#size-cells = <0>;

			port@0 {
				reg = <0>;

				tcpc_hs_ep: endpoint {
					remote-endpoint = <&ssusb_hs_ep>;
				};
			};

			port@1 {
				reg = <1>;

				tcpc_ss_ep: endpoint {
					remote-endpoint = <&ssusb_ss_ep>;
				};
			};
		};
	};
};

/*
 * CONSYS (wifi/BT/GPS block) and its wifi interface, for the vendor gen3 stack ported under
 * drivers/net/wireless/mediatek/mt6771-consys (17-consys-port). Registers, interrupts and the second
 * to fourth reg ranges (RGU, infracfg, SPM) are the vendor's (live.dts consys@18070000, wifi@180f0000).
 * The vendor's "conn" clock is its power-domain wrapper; here the CONN domain is attached by the
 * platform bus. The wifi node's "wifi-dma" clock is the vendor's INFRACFG_AO_CQ_DMA_CG, which mainline
 * provides as CLK_INFRA_CQ_DMA (infra_cqdma, INFRA2 bit 27).
 * Bring-up state: the stack is loaded from Debian as modules; nothing here is verified on hardware.
 */
/* All connectivity interrupts are level-low in the vendor tree (0x08); sysirq inverts them. Level-high
 * here made one line fire at ~100 kHz (2026-09-26) and drowned BTIF receive. */
&{/soc} {
	consys_hw: consys@18070000 {
		compatible = "mediatek,mt6771-consys";
		reg = <0 0x18070000 0 0x1000>,
		      <0 0x10007000 0 0x100>,
		      <0 0x10001000 0 0x1000>,
		      <0 0x10006000 0 0x1000>;
		interrupts = <GIC_SPI 289 IRQ_TYPE_LEVEL_LOW>,
			     <GIC_SPI 291 IRQ_TYPE_LEVEL_LOW>;
		power-domains = <&spm MT8183_POWER_DOMAIN_CONN>;
		/* The vendor driver asks for vcn18, vcn28, vcn33_bt and vcn33_wifi; the MT6358 has one
		 * VCN33 LDO, which the vendor exposes as two enable bits, so both names map to ldo_vcn33. */
		vcn18-supply = <&mt6358_vcn18_reg>;
		vcn28-supply = <&mt6358_vcn28_reg>;
		vcn33_bt-supply = <&mt6358_vcn33_reg>;
		vcn33_wifi-supply = <&mt6358_vcn33_reg>;
		/* GPS LNA enable (GPIO155), driven by WMT when GPS turns on (live.dts:3435-3466). The
		 * driver reads the pin number from pinctrl-1's pins-cmd-dat for mnld. */
		pinctrl-names = "default", "gps_lna_state_init", "gps_lna_state_oh", "gps_lna_state_ol";
		pinctrl-0 = <&consys_default_pins>;
		pinctrl-1 = <&gps_lna_init_pins>;
		pinctrl-2 = <&gps_lna_oh_pins>;
		pinctrl-3 = <&gps_lna_ol_pins>;
		status = "okay";
	};

	/* BTIF: the AP <-> connectivity MCU link the WMT/STP transport rides on. Vendor node
	 * (live.dts:4115): the BTIF block plus its two APDMA channels (tx, rx); clocks btifc, apdmac. */
	btif_hw: btif@1100c000 {
		compatible = "mediatek,btif";
		reg = <0 0x1100c000 0 0x1000>,
		      <0 0x11000a80 0 0x80>,
		      <0 0x11000b00 0 0x80>;
		interrupts = <GIC_SPI 114 IRQ_TYPE_LEVEL_LOW>,
			     <GIC_SPI 139 IRQ_TYPE_LEVEL_LOW>,
			     <GIC_SPI 140 IRQ_TYPE_LEVEL_LOW>;
		clocks = <&infracfg CLK_INFRA_BTIF>, <&infracfg CLK_INFRA_AP_DMA>;
		clock-names = "btifc", "apdmac";
		status = "okay";
	};

	wifi_hw: wifi@180f0000 {
		compatible = "mediatek,wifi";
		reg = <0 0x180f0000 0 0x1100>,
		      <0 0x10212180 0 0x6c>,
		      <0 0x10001000 0 0x1000>,
		      <0 0x180e0000 0 0x70>;
		interrupts = <GIC_SPI 290 IRQ_TYPE_LEVEL_LOW>,
			     <GIC_SPI 118 IRQ_TYPE_LEVEL_LOW>;
		clocks = <&infracfg CLK_INFRA_CQ_DMA>;
		clock-names = "wifi-dma";
		hardware-values = <0x788 0xa5800 0xa5800>;
		status = "okay";
	};
};

/ {
	/*
	 * The keyboard matrix itself, from the vendor key_map[] (aw9523_key.c): P0_0..7 are the rows
	 * (inputs, interrupt on change), P1_0..6 the columns, driven low one at a time. Four positions
	 * (row 7, columns 3..6) are unpopulated. KEY_LEFTMETA is the vendor's "meta" (Fn) key.
	 */
	keyboard {
		compatible = "gpio-matrix-keypad";
		/* the Gemian keyboard driver rescans every 10 ms while a key is held (aw9523_key.c) */
		rescan-while-pressed-ms = <10>;
		row-gpios = <&aw9523 0 GPIO_ACTIVE_LOW>, <&aw9523 1 GPIO_ACTIVE_LOW>,
			    <&aw9523 2 GPIO_ACTIVE_LOW>, <&aw9523 3 GPIO_ACTIVE_LOW>,
			    <&aw9523 4 GPIO_ACTIVE_LOW>, <&aw9523 5 GPIO_ACTIVE_LOW>,
			    <&aw9523 6 GPIO_ACTIVE_LOW>, <&aw9523 7 GPIO_ACTIVE_LOW>;
		col-gpios = <&aw9523 8 GPIO_ACTIVE_LOW>, <&aw9523 9 GPIO_ACTIVE_LOW>,
			    <&aw9523 10 GPIO_ACTIVE_LOW>, <&aw9523 11 GPIO_ACTIVE_LOW>,
			    <&aw9523 12 GPIO_ACTIVE_LOW>, <&aw9523 13 GPIO_ACTIVE_LOW>,
			    <&aw9523 14 GPIO_ACTIVE_LOW>;
		/*
		 * Settle time between driving a column and reading the rows. With 10 us the first row
		 * read after a column went low still showed its neighbour's edge: "s" (row 2) also
		 * typed "1" (row 0). The vendor driver has two I2C writes (~0.5 ms) in between.
		 */
		col-scan-delay-us = <500>;
		debounce-delay-ms = <10>;
		gpio-activelow;
		wakeup-source;
		linux,keymap = <
			MATRIX_KEY(0, 0, KEY_1)
			MATRIX_KEY(0, 1, KEY_2)
			MATRIX_KEY(0, 2, KEY_3)
			MATRIX_KEY(0, 3, KEY_4)
			MATRIX_KEY(0, 4, KEY_5)
			MATRIX_KEY(0, 5, KEY_6)
			MATRIX_KEY(0, 6, KEY_7)
			MATRIX_KEY(1, 0, KEY_U)
			MATRIX_KEY(1, 1, KEY_W)
			MATRIX_KEY(1, 2, KEY_Y)
			MATRIX_KEY(1, 3, KEY_T)
			MATRIX_KEY(1, 4, KEY_E)
			MATRIX_KEY(1, 5, KEY_Q)
			MATRIX_KEY(1, 6, KEY_R)
			MATRIX_KEY(2, 0, KEY_S)
			MATRIX_KEY(2, 1, KEY_D)
			MATRIX_KEY(2, 2, KEY_TAB)
			MATRIX_KEY(2, 3, KEY_F)
			MATRIX_KEY(2, 4, KEY_G)
			MATRIX_KEY(2, 5, KEY_A)
			MATRIX_KEY(2, 6, KEY_H)
			MATRIX_KEY(3, 0, KEY_Z)
			MATRIX_KEY(3, 1, KEY_C)
			MATRIX_KEY(3, 2, KEY_N)
			MATRIX_KEY(3, 3, KEY_X)
			MATRIX_KEY(3, 4, KEY_V)
			MATRIX_KEY(3, 5, KEY_B)
			MATRIX_KEY(3, 6, KEY_LEFTSHIFT)
			MATRIX_KEY(4, 0, KEY_COMMA)
			MATRIX_KEY(4, 1, KEY_LEFTALT)
			MATRIX_KEY(4, 2, KEY_M)
			MATRIX_KEY(4, 3, KEY_LEFTMETA)
			MATRIX_KEY(4, 4, KEY_SPACE)
			MATRIX_KEY(4, 5, KEY_DOT)
			MATRIX_KEY(4, 6, KEY_LEFTCTRL)
			MATRIX_KEY(5, 0, KEY_APOSTROPHE)
			MATRIX_KEY(5, 1, KEY_LEFT)
			MATRIX_KEY(5, 2, KEY_DOWN)
			MATRIX_KEY(5, 3, KEY_RIGHTSHIFT)
			MATRIX_KEY(5, 4, KEY_UP)
			MATRIX_KEY(5, 5, KEY_RIGHT)
			MATRIX_KEY(5, 6, KEY_L)
			MATRIX_KEY(6, 0, KEY_8)
			MATRIX_KEY(6, 1, KEY_9)
			MATRIX_KEY(6, 2, KEY_BACKSPACE)
			MATRIX_KEY(6, 3, KEY_P)
			MATRIX_KEY(6, 4, KEY_O)
			MATRIX_KEY(6, 5, KEY_ENTER)
			MATRIX_KEY(6, 6, KEY_0)
			MATRIX_KEY(7, 0, KEY_J)
			MATRIX_KEY(7, 1, KEY_K)
			MATRIX_KEY(7, 2, KEY_I)
		>;
	};
};

/* Reset through the watchdog, ahead of the firmware: the vendor's PSCI SYSTEM_RESET hangs. */
&watchdog {
	compatible = "mediatek,mt6771-wdt";
};

/*
 * The SoC temperature sensors are read through this ADC. With it disabled the thermal sensor never
 * probed and the phone had no thermal zones at all: nothing between a runaway load and the silicon.
 * The vendor resets the phone at 117 C; mt8183.dtsi's zones carry a 115 C critical trip.
 */
&auxadc {
	status = "okay";
};

&modem {
	mediatek,pmic = <&pmic>;
	status = "okay";

	/* the nano-SIM slot; SIM2 is the soldered eSIM, which has no hot-plug interrupt */
	sim-hot-plug-1 {
		mediatek,eint = <0>;
		mediatek,eint-trigger = <IRQ_TYPE_LEVEL_LOW>;
		mediatek,debounce-us = <100000>;
		mediatek,socket-type = <0>;
		mediatek,dedicated = <0>;
		mediatek,source-pin = <1>;
	};
};

/*
 * Keys and lid (hw-spec/input-misc.org). The PMIC home key is volume up on this board (vendor
 * hal_kpd.c); one-key 8 s power reset as the vendor programs it (TOP_RST_MISC 0x221).
 */
/* LK and the vendor OS store the RTC year from 1968 (vendor mtk_rtc_common.c RTC_MIN_YEAR) */
&mt6358rtc {
	mediatek,year-base = <1968>;
};

&mt6358keys {
	mediatek,long-press-mode = <1>;
	power-off-time-sec = <0>;

	home {
		linux,keycodes = <KEY_VOLUMEUP>;
	};
};

/ {
	gpio-keys {
		compatible = "gpio-keys";
		pinctrl-names = "default";
		pinctrl-0 = <&gpio_keys_pins>;

		/* hall sensor, low while the lid is closed (vendor hall-eint, debounce 64 ms) */
		lid {
			label = "Lid";
			gpios = <&pio 8 GPIO_ACTIVE_LOW>;
			linux,input-type = <EV_SW>;
			linux,code = <SW_LID>;
			debounce-interval = <64>;
			wakeup-source;
		};

		volume-down {
			label = "Volume Down";
			gpios = <&pio 11 GPIO_ACTIVE_LOW>;
			linux,code = <KEY_VOLUMEDOWN>;
			debounce-interval = <20>;
		};
	};

	/* MT6358 VIBR LDO, fixed 2.8 V as the vendor drives it */
	vibrator {
		compatible = "regulator-haptic";
		haptic-supply = <&mt6358_vibr_reg>;
		min-microvolt = <2800000>;
		max-microvolt = <2800000>;
	};
};

&pio {
	nfc_pins: nfc-pins {
		pins-irq {
			pinmux = <PINMUX_GPIO71__FUNC_GPIO71>;
			input-enable;
			bias-pull-down;
		};
	};

	/* the vendor pn553 driver holds the ISO reset high and the eSE power off */
	nfc-iso-rst-hog {
		gpio-hog;
		gpios = <66 GPIO_ACTIVE_HIGH>;
		output-high;
		line-name = "nfc-iso-rst";
	};

	nfc-ese-pwr-hog {
		gpio-hog;
		gpios = <65 GPIO_ACTIVE_HIGH>;
		output-low;
		line-name = "nfc-ese-pwr";
	};

	spi1_pins: spi1-pins {
		pins-miso {
			pinmux = <PINMUX_GPIO161__FUNC_SPI1_A_MI>;
			input-enable;
		};

		pins-out {
			pinmux = <PINMUX_GPIO162__FUNC_SPI1_A_CSB>,
				 <PINMUX_GPIO163__FUNC_SPI1_A_MO>,
				 <PINMUX_GPIO164__FUNC_SPI1_A_CLK>;
		};
	};

	imu_pins: imu-pins {
		pins-irq {
			pinmux = <PINMUX_GPIO4__FUNC_GPIO4>;
			input-enable;
			bias-pull-up;
		};
	};

	light_sensor_pins: light-sensor-pins {
		pins-irq {
			pinmux = <PINMUX_GPIO6__FUNC_GPIO6>;
			input-enable;
			bias-pull-up;
		};
	};

	gpio_keys_pins: gpio-keys-pins {
		pins-keys {
			pinmux = <PINMUX_GPIO8__FUNC_GPIO8>,
				 <PINMUX_GPIO11__FUNC_GPIO11>;
			input-enable;
			bias-pull-up;
		};
	};
};

/*
 * Battery temperature (hw-spec/power.org): 10 kOhm NTC on the MT6358 BATON pin to ground, pulled up
 * by 24 kOhm to VBIF28 (2.8 V), the vendor's Fg_Temperature_Table = Murata NCP15XH103. The vendor
 * powers the phone off at 60 C (BATTERY_SHUTDOWN_TEMPERATURE).
 */
/ {
	/* BATON voltage in mV, from the NCP15XH103 curve: V = 2800 * R / (R + 24000) */
	battery_ntc: battery-ntc {
		compatible = "generic-adc-thermal";
		#thermal-sensor-cells = <0>;
		io-channels = <&pmic_adc MT6358_AUXADC_BAT_TEMP>;
		io-channel-names = "sensor-channel";
		temperature-lookup-table = <
			(-20000) 2071  (-15000) 1935  (-10000) 1790  (-5000) 1639
			0 1488  5000 1340  10000 1197  15000 1062
			20000 938  25000 824  30000 720  35000 629
			40000 548  45000 476  50000 414  55000 359
			60000 312  65000 272  70000 238  75000 208
			80000 182  85000 160  90000 141>;
	};

	thermal-zones {
		battery-thermal {
			polling-delay-passive = <2000>;
			polling-delay = <5000>;
			thermal-sensors = <&battery_ntc>;

			trips {
				battery_crit: battery-crit {
					temperature = <60000>;
					hysteresis = <2000>;
					type = "critical";
				};
			};
		};
	};
};

/* Accelerometer and gyroscope (vendor accelgyro@0 on spi1, direction 4) */
&spi1 {
	pinctrl-names = "default";
	pinctrl-0 = <&spi1_pins>;
	mediatek,pad-select = <0>;	/* the SPI1_A pads, GPIO161-164 */
	status = "okay";

	imu@0 {
		compatible = "bosch,bmi160";
		reg = <0>;
		spi-max-frequency = <8000000>;
		interrupts-extended = <&pio 4 IRQ_TYPE_LEVEL_LOW>;
		interrupt-names = "INT1";
		pinctrl-names = "default";
		pinctrl-0 = <&imu_pins>;
		/* vendor direction 4: x and z inverted; to be proven with a gravity test */
		mount-matrix = "-1", "0", "0",
			       "0", "1", "0",
			       "0", "0", "-1";
	};
};

/* Vproc12 feeds the little cluster and the CCI, Vproc11 the big cluster; the PMIC tracks Vsram */
&cci {
	proc-supply = <&mt6358_vproc12_reg>;
};

&cpu0 {
	proc-supply = <&mt6358_vproc12_reg>;
};

&cpu1 {
	proc-supply = <&mt6358_vproc12_reg>;
};

&cpu2 {
	proc-supply = <&mt6358_vproc12_reg>;
};

&cpu3 {
	proc-supply = <&mt6358_vproc12_reg>;
};

&cpu4 {
	proc-supply = <&mt6358_vproc11_reg>;
};

&cpu5 {
	proc-supply = <&mt6358_vproc11_reg>;
};

&cpu6 {
	proc-supply = <&mt6358_vproc11_reg>;
};

&cpu7 {
	proc-supply = <&mt6358_vproc11_reg>;
};

/*
 * This chip's speed bin is V5_T (efuse turbo bit, vendor log "[Power/cpufreq] 6"). Tables from
 * mtk_cpufreq_opp_table.h:472-561: LL and CCI take the VPROC1 column, L the VPROC2 column. mt8183.dtsi
 * carries V5_4, at or above these voltages everywhere but without L 1651 and 2106 MHz.
 */
/ {
	cluster0_opp_v5t: opp-table-cluster0v5t {
		compatible = "operating-points-v2";
		opp-shared;

		opp-793000000 {
			opp-hz = /bits/ 64 <793000000>;
			opp-microvolt = <600000>;
			required-opps = <&cci_v5t_15>;
		};
		opp-910000000 {
			opp-hz = /bits/ 64 <910000000>;
			opp-microvolt = <637500>;
			required-opps = <&cci_v5t_14>;
		};
		opp-1014000000 {
			opp-hz = /bits/ 64 <1014000000>;
			opp-microvolt = <668750>;
			required-opps = <&cci_v5t_13>;
		};
		opp-1131000000 {
			opp-hz = /bits/ 64 <1131000000>;
			opp-microvolt = <706250>;
			required-opps = <&cci_v5t_12>;
		};
		opp-1248000000 {
			opp-hz = /bits/ 64 <1248000000>;
			opp-microvolt = <737500>;
			required-opps = <&cci_v5t_11>;
		};
		opp-1326000000 {
			opp-hz = /bits/ 64 <1326000000>;
			opp-microvolt = <768750>;
			required-opps = <&cci_v5t_10>;
		};
		opp-1417000000 {
			opp-hz = /bits/ 64 <1417000000>;
			opp-microvolt = <800000>;
			required-opps = <&cci_v5t_09>;
		};
		opp-1508000000 {
			opp-hz = /bits/ 64 <1508000000>;
			opp-microvolt = <818750>;
			required-opps = <&cci_v5t_08>;
		};
		opp-1586000000 {
			opp-hz = /bits/ 64 <1586000000>;
			opp-microvolt = <843750>;
			required-opps = <&cci_v5t_07>;
		};
		opp-1625000000 {
			opp-hz = /bits/ 64 <1625000000>;
			opp-microvolt = <856250>;
			required-opps = <&cci_v5t_06>;
		};
		opp-1677000000 {
			opp-hz = /bits/ 64 <1677000000>;
			opp-microvolt = <881250>;
			required-opps = <&cci_v5t_05>;
		};
		opp-1716000000 {
			opp-hz = /bits/ 64 <1716000000>;
			opp-microvolt = <893750>;
			required-opps = <&cci_v5t_04>;
		};
		opp-1781000000 {
			opp-hz = /bits/ 64 <1781000000>;
			opp-microvolt = <925000>;
			required-opps = <&cci_v5t_03>;
		};
		opp-1846000000 {
			opp-hz = /bits/ 64 <1846000000>;
			opp-microvolt = <950000>;
			required-opps = <&cci_v5t_02>;
		};
		opp-1924000000 {
			opp-hz = /bits/ 64 <1924000000>;
			opp-microvolt = <975000>;
			required-opps = <&cci_v5t_01>;
		};
		opp-1989000000 {
			opp-hz = /bits/ 64 <1989000000>;
			opp-microvolt = <1000000>;
			required-opps = <&cci_v5t_00>;
		};
	};

	/*
	 * CCI for an L OPP: the fastest CCI OPP whose (LL column) voltage does not exceed the L
	 * voltage, as the vendor AP path picks it (mtk_cpufreq_main.c:182-205).
	 */
	cluster1_opp_v5t: opp-table-cluster1v5t {
		compatible = "operating-points-v2";
		opp-shared;

		opp-793000000 {
			opp-hz = /bits/ 64 <793000000>;
			opp-microvolt = <675000>;
			required-opps = <&cci_v5t_14>;
		};
		opp-910000000 {
			opp-hz = /bits/ 64 <910000000>;
			opp-microvolt = <700000>;
			required-opps = <&cci_v5t_13>;
		};
		opp-1014000000 {
			opp-hz = /bits/ 64 <1014000000>;
			opp-microvolt = <725000>;
			required-opps = <&cci_v5t_12>;
		};
		opp-1131000000 {
			opp-hz = /bits/ 64 <1131000000>;
			opp-microvolt = <750000>;
			required-opps = <&cci_v5t_11>;
		};
		opp-1248000000 {
			opp-hz = /bits/ 64 <1248000000>;
			opp-microvolt = <775000>;
			required-opps = <&cci_v5t_10>;
		};
		opp-1326000000 {
			opp-hz = /bits/ 64 <1326000000>;
			opp-microvolt = <800000>;
			required-opps = <&cci_v5t_09>;
		};
		opp-1417000000 {
			opp-hz = /bits/ 64 <1417000000>;
			opp-microvolt = <825000>;
			required-opps = <&cci_v5t_08>;
		};
		opp-1508000000 {
			opp-hz = /bits/ 64 <1508000000>;
			opp-microvolt = <850000>;
			required-opps = <&cci_v5t_07>;
		};
		opp-1586000000 {
			opp-hz = /bits/ 64 <1586000000>;
			opp-microvolt = <875000>;
			required-opps = <&cci_v5t_06>;
		};
		opp-1651000000 {
			opp-hz = /bits/ 64 <1651000000>;
			opp-microvolt = <900000>;
			required-opps = <&cci_v5t_04>;
		};
		opp-1716000000 {
			opp-hz = /bits/ 64 <1716000000>;
			opp-microvolt = <925000>;
			required-opps = <&cci_v5t_03>;
		};
		opp-1781000000 {
			opp-hz = /bits/ 64 <1781000000>;
			opp-microvolt = <950000>;
			required-opps = <&cci_v5t_02>;
		};
		opp-1846000000 {
			opp-hz = /bits/ 64 <1846000000>;
			opp-microvolt = <975000>;
			required-opps = <&cci_v5t_01>;
		};
		opp-1924000000 {
			opp-hz = /bits/ 64 <1924000000>;
			opp-microvolt = <1000000>;
			required-opps = <&cci_v5t_00>;
		};
		opp-1989000000 {
			opp-hz = /bits/ 64 <1989000000>;
			opp-microvolt = <1025000>;
			required-opps = <&cci_v5t_00>;
		};
		/* turbo bin OPP0: the vendor pins it to cpu_t_volt 1050 mV (mtk_eem.c:1579-1580) */
		opp-2106000000 {
			opp-hz = /bits/ 64 <2106000000>;
			opp-microvolt = <1050000>;
			required-opps = <&cci_v5t_00>;
#if COSMO_CPU_OPP_V5T == 1
			/* no supported-hw set by mediatek-cpufreq, so the OPP core skips this OPP */
			opp-supported-hw = <0>;
#endif
		};
	};

	cci_opp_v5t: opp-table-cciv5t {
		compatible = "operating-points-v2";
		opp-shared;

		cci_v5t_15: opp-273000000 {
			opp-hz = /bits/ 64 <273000000>;
			opp-microvolt = <600000>;
		};
		cci_v5t_14: opp-338000000 {
			opp-hz = /bits/ 64 <338000000>;
			opp-microvolt = <637500>;
		};
		cci_v5t_13: opp-403000000 {
			opp-hz = /bits/ 64 <403000000>;
			opp-microvolt = <668750>;
		};
		cci_v5t_12: opp-481000000 {
			opp-hz = /bits/ 64 <481000000>;
			opp-microvolt = <706250>;
		};
		cci_v5t_11: opp-546000000 {
			opp-hz = /bits/ 64 <546000000>;
			opp-microvolt = <737500>;
		};
		cci_v5t_10: opp-624000000 {
			opp-hz = /bits/ 64 <624000000>;
			opp-microvolt = <768750>;
		};
		cci_v5t_09: opp-689000000 {
			opp-hz = /bits/ 64 <689000000>;
			opp-microvolt = <800000>;
		};
		cci_v5t_08: opp-767000000 {
			opp-hz = /bits/ 64 <767000000>;
			opp-microvolt = <818750>;
		};
		cci_v5t_07: opp-845000000 {
			opp-hz = /bits/ 64 <845000000>;
			opp-microvolt = <843750>;
		};
		cci_v5t_06: opp-871000000 {
			opp-hz = /bits/ 64 <871000000>;
			opp-microvolt = <856250>;
		};
		cci_v5t_05: opp-923000000 {
			opp-hz = /bits/ 64 <923000000>;
			opp-microvolt = <881250>;
		};
		cci_v5t_04: opp-962000000 {
			opp-hz = /bits/ 64 <962000000>;
			opp-microvolt = <893750>;
		};
		cci_v5t_03: opp-1027000000 {
			opp-hz = /bits/ 64 <1027000000>;
			opp-microvolt = <925000>;
		};
		cci_v5t_02: opp-1092000000 {
			opp-hz = /bits/ 64 <1092000000>;
			opp-microvolt = <950000>;
		};
		cci_v5t_01: opp-1144000000 {
			opp-hz = /bits/ 64 <1144000000>;
			opp-microvolt = <975000>;
		};
		cci_v5t_00: opp-1196000000 {
			opp-hz = /bits/ 64 <1196000000>;
			opp-microvolt = <1000000>;
		};
	};
};

#if COSMO_CPU_OPP_V5T
&cci {
	operating-points-v2 = <&cci_opp_v5t>;
};

&cpu0 {
	operating-points-v2 = <&cluster0_opp_v5t>;
};

&cpu1 {
	operating-points-v2 = <&cluster0_opp_v5t>;
};

&cpu2 {
	operating-points-v2 = <&cluster0_opp_v5t>;
};

&cpu3 {
	operating-points-v2 = <&cluster0_opp_v5t>;
};

&cpu4 {
	operating-points-v2 = <&cluster1_opp_v5t>;
};

&cpu5 {
	operating-points-v2 = <&cluster1_opp_v5t>;
};

&cpu6 {
	operating-points-v2 = <&cluster1_opp_v5t>;
};

&cpu7 {
	operating-points-v2 = <&cluster1_opp_v5t>;
};
#endif

/*
 * Per-sensor zones from mt8183.dtsi (TSn is the vendor TS_MCUn: same mux codes, mtk_tc.c:97-118 and
 * tscpu_settings.h:173-177). tsabb stays off: mainline muxes it with code 0 (the MCU1 point) where
 * the vendor uses 0x10 (tscpu_settings.h:178).
 */
#if !COSMO_SENSOR_ZONES
&tzts1 {
	status = "disabled";
};

&tzts2 {
	status = "disabled";
};

&tzts3 {
	status = "disabled";
};

&tzts4 {
	status = "disabled";
};

&tzts5 {
	status = "disabled";
};
#endif

&tztsABB {
	status = "disabled";
};

#if !COSMO_SVS
&svs {
	status = "disabled";
};
#endif

/*
 * The vendor's mcdi-cpu and mcdi-cluster PSCI params and latencies (vendor mt6771.dts:165-178);
 * min-residency per cluster from its MCDI governor (mtk_mcdi_state.c:34-47, 82-95). The stock ATF
 * leaves the power cut to the SSPM MCDI task, and for cluster-off the vendor kernel also writes the
 * SSPM CAN_POWER_OFF mailbox slot, which nothing here does (hw-spec/power.org, CPU idle).
 */
#if COSMO_CPUIDLE
/ {
	cpus {
		idle-states {
			entry-method = "psci";

			MCDI_CPU_LL: cpu-mcdi-ll {
				compatible = "arm,idle-state";
				local-timer-stop;
				arm,psci-suspend-param = <0x00010001>;
				entry-latency-us = <600>;
				exit-latency-us = <600>;
				min-residency-us = <4500>;
			};

			MCDI_CPU_L: cpu-mcdi-l {
				compatible = "arm,idle-state";
				local-timer-stop;
				arm,psci-suspend-param = <0x00010001>;
				entry-latency-us = <600>;
				exit-latency-us = <600>;
				min-residency-us = <1500>;
			};

#if COSMO_CPUIDLE == 2
			MCDI_CLUSTER_LL: cluster-mcdi-ll {
				compatible = "arm,idle-state";
				local-timer-stop;
				arm,psci-suspend-param = <0x01010001>;
				entry-latency-us = <600>;
				exit-latency-us = <600>;
				min-residency-us = <4500>;
			};

			MCDI_CLUSTER_L: cluster-mcdi-l {
				compatible = "arm,idle-state";
				local-timer-stop;
				arm,psci-suspend-param = <0x01010001>;
				entry-latency-us = <600>;
				exit-latency-us = <600>;
				min-residency-us = <1500>;
			};
#endif
		};
	};
};

#if COSMO_CPUIDLE == 2
#define COSMO_IDLE_LL	<&MCDI_CPU_LL &MCDI_CLUSTER_LL>
#define COSMO_IDLE_L	<&MCDI_CPU_L &MCDI_CLUSTER_L>
#else
#define COSMO_IDLE_LL	<&MCDI_CPU_LL>
#define COSMO_IDLE_L	<&MCDI_CPU_L>
#endif

&cpu0 {
	cpu-idle-states = COSMO_IDLE_LL;
};

&cpu1 {
	cpu-idle-states = COSMO_IDLE_LL;
};

&cpu2 {
	cpu-idle-states = COSMO_IDLE_LL;
};

&cpu3 {
	cpu-idle-states = COSMO_IDLE_LL;
};

&cpu4 {
	cpu-idle-states = COSMO_IDLE_L;
};

&cpu5 {
	cpu-idle-states = COSMO_IDLE_L;
};

&cpu6 {
	cpu-idle-states = COSMO_IDLE_L;
};

&cpu7 {
	cpu-idle-states = COSMO_IDLE_L;
};
#endif

/*
 * Audio (hw-spec/audio.org). The speakers are fed from the codec headphone buffer through two
 * one-wire amplifiers pulsed three times (vendor AudDrv_GPIO_EXTAMP_Select, mode 3); GPIO108 is
 * the earpiece path switch the vendor raises only while the receiver is on.
 */
&mt6358codec {
	Avdd-supply = <&mt6358_vaud28_reg>;
};

/* Jack detection, vendor accdet node values (hw-spec/audio.org 2.4); fuel gauge */
&pmic {
	battery {
		compatible = "mediatek,mt6358-battery";
		io-channels = <&pmic_adc MT6358_AUXADC_BATADC>;
		io-channel-names = "vbat";
		monitored-battery = <&battery>;
	};

	mt6358_accdet: accdet {
		compatible = "mediatek,mt6358-accdet";
		io-channels = <&pmic_adc MT6358_AUXADC_ACCDET>;
		io-channel-names = "accdet";
		mediatek,mic-vol = <6>;
		mediatek,eint-level-pol = <IRQ_TYPE_LEVEL_LOW>;
		mediatek,pwm-deb-setting = <0x500 0x500 1 0x1f0 0x800 0x800 0x20 0x44>;
		mediatek,three-key-thr = <0 80 220 400>;
	};
};

/*
 * Keyboard backlight (vendor aw9524_key.c gpio_main_pwm_keyboardlight): SoC PWM channel 0 on GPIO90 in
 * five 20 % steps, and GPIO178 high whenever the light is on. GPIO178 is shared with the HDMI hot-plug
 * path in the vendor code; what it switches on the board is not in the source, so it is held high.
 */
&pio {
	uart1_pins: uart1-pins {
		pins-rx {
			pinmux = <PINMUX_GPIO110__FUNC_URXD1>;
			input-enable;
			bias-pull-up;
		};

		pins-tx {
			pinmux = <PINMUX_GPIO112__FUNC_UTXD1>;
		};
	};
};

&pio {
	kbd_backlight_pins: kbd-backlight-pins {
		pins-pwm {
			pinmux = <PINMUX_GPIO90__FUNC_PWM_A>;
		};
	};

	kbd-light-enable-hog {
		gpio-hog;
		gpios = <178 GPIO_ACTIVE_HIGH>;
		output-high;
		line-name = "keyboard-light-enable";
	};
};

&pwm1 {
	pinctrl-names = "default";
	pinctrl-0 = <&kbd_backlight_pins>;
};

/ {
	pwm-leds {
		compatible = "pwm-leds";

		led {
			function = LED_FUNCTION_KBD_BACKLIGHT;
			color = <LED_COLOR_ID_WHITE>;
			pwms = <&pwm1 0 20000>;
			max-brightness = <5>;
		};
	};
};

&pio {
	touch_pins: touch-pins {
		pins-irq {
			pinmux = <PINMUX_GPIO9__FUNC_GPIO9>;
			input-enable;
			bias-pull-up;
		};
	};
};

&pio {
	aud_pins: audio-pins {
		pins-mtkaif {
			pinmux = <PINMUX_GPIO136__FUNC_AUD_CLK_MOSI>,
				 <PINMUX_GPIO137__FUNC_AUD_SYNC_MOSI>,
				 <PINMUX_GPIO138__FUNC_AUD_DAT_MOSI0>,
				 <PINMUX_GPIO139__FUNC_AUD_DAT_MOSI1>,
				 <PINMUX_GPIO140__FUNC_AUD_CLK_MISO>,
				 <PINMUX_GPIO141__FUNC_AUD_SYNC_MISO>,
				 <PINMUX_GPIO142__FUNC_AUD_DAT_MISO0>,
				 <PINMUX_GPIO143__FUNC_AUD_DAT_MISO1>;
		};
	};
};

/ {
	speaker_amp1: audio-amplifier-1 {
		compatible = "awinic,aw8738";
		mode-gpios = <&pio 153 GPIO_ACTIVE_HIGH>;
		awinic,mode = <3>;
		sound-name-prefix = "Amp1";
	};

	speaker_amp2: audio-amplifier-2 {
		compatible = "awinic,aw8738";
		mode-gpios = <&pio 111 GPIO_ACTIVE_HIGH>;
		awinic,mode = <3>;
		sound-name-prefix = "Amp2";
	};

	earpiece_switch: audio-switch {
		compatible = "simple-audio-amplifier";
		enable-gpios = <&pio 108 GPIO_ACTIVE_HIGH>;
		sound-name-prefix = "Earpiece Switch";
	};

	sound {
		compatible = "planet,cosmo-sound";
		mediatek,platform = <&afe>;
		mediatek,accdet = <&mt6358_accdet>;
		aux-devs = <&speaker_amp1>, <&speaker_amp2>, <&earpiece_switch>;
		pinctrl-names = "default";
		pinctrl-0 = <&aud_pins>;
	};
};

/*
 * HDMI out on the right USB-C port: DPI0 (12-bit dual edge) -> SiI9022A at i2c3 0x39 -> GPIO lane
 * switch -> connector. Everything here is disabled until it is tested with a right-port HDMI adapter.
 * The LK dtbo's sii9022_hdmi@39 and siiedid@50 land on i2c3_lkstub (ci/mkbootimg-cosmo.py), not on
 * this bus; this node must not take the label "sii9022", which the dtbo sets to okay.
 */
/ {
	/* vendor sil9022_1v2_en; it is the only bridge rail the vendor switches, left on by LK */
	hdmi_1v2: regulator-hdmi-1v2 {
		compatible = "regulator-fixed";
		regulator-name = "hdmi_1v2";
		regulator-min-microvolt = <1200000>;
		regulator-max-microvolt = <1200000>;
		gpio = <&pio 160 GPIO_ACTIVE_HIGH>;
		enable-active-high;
		regulator-boot-on;
		/* vendor: 70 ms from power on to reset release */
		startup-delay-us = <70000>;
		status = "disabled";
	};

	hdmi-connector {
		compatible = "hdmi-connector";
		label = "hdmi";
		type = "a";
		status = "disabled";

		port {
			hdmi_connector_in: endpoint {
				remote-endpoint = <&hdmi_bridge_out>;
			};
		};
	};
};

&i2c3 {
	hdmi_bridge: hdmi-bridge@39 {
		compatible = "sil,sii9022";
		reg = <0x39>;
		interrupts-extended = <&pio 78 IRQ_TYPE_LEVEL_LOW>;
		reset-gpios = <&pio 159 GPIO_ACTIVE_LOW>;
		iovcc-supply = <&hdmi_1v2>;
		cvcc12-supply = <&hdmi_1v2>;
		pinctrl-names = "default";
		pinctrl-0 = <&hdmi_bridge_pins>;
		status = "disabled";

		ports {
			#address-cells = <1>;
			#size-cells = <0>;

			port@0 {
				reg = <0>;

				hdmi_bridge_in: endpoint {
					bus-width = <12>;
					remote-endpoint = <&dpi_out>;
				};
			};

			port@1 {
				reg = <1>;

				hdmi_bridge_out: endpoint {
					remote-endpoint = <&hdmi_connector_in>;
				};
			};
		};
	};
};

&dpi0 {
	pinctrl-names = "default", "sleep";
	pinctrl-0 = <&dpi_func_pins>;
	pinctrl-1 = <&dpi_idle_pins>;
	status = "disabled";
};

&dpi_out {
	remote-endpoint = <&hdmi_bridge_in>;
};

&pio {
	/*
	 * Lane switch GPIO177 low (enabled), GPIO176 low: the vendor's state for an HDMI adapter at CC1
	 * (Android usb_typec.c:335-343). CC2 needs GPIO176 high. Orientation is only known from the
	 * FUSB301A, which has no driver yet, so this is fixed and is applied when the bridge probes.
	 */
	hdmi_bridge_pins: hdmi-bridge-pins {
		pins-irq {
			pinmux = <PINMUX_GPIO78__FUNC_GPIO78>;
			input-enable;
			bias-disable;
		};

		pins-switch {
			pinmux = <PINMUX_GPIO176__FUNC_GPIO176>,
				 <PINMUX_GPIO177__FUNC_GPIO177>;
			output-low;
		};
	};

	/* vendor sil9022_dpi_func1 / sil9022_dpi_gpio: raw drive 7 is 16 mA */
	dpi_func_pins: dpi-func-pins {
		pins-dpi {
			pinmux = <PINMUX_GPIO13__FUNC_DBPI_D0>,
				 <PINMUX_GPIO14__FUNC_DBPI_D1>,
				 <PINMUX_GPIO15__FUNC_DBPI_D2>,
				 <PINMUX_GPIO16__FUNC_DBPI_D3>,
				 <PINMUX_GPIO17__FUNC_DBPI_D4>,
				 <PINMUX_GPIO18__FUNC_DBPI_D5>,
				 <PINMUX_GPIO19__FUNC_DBPI_D6>,
				 <PINMUX_GPIO20__FUNC_DBPI_D7>,
				 <PINMUX_GPIO21__FUNC_DBPI_D8>,
				 <PINMUX_GPIO22__FUNC_DBPI_D9>,
				 <PINMUX_GPIO23__FUNC_DBPI_D10>,
				 <PINMUX_GPIO24__FUNC_DBPI_D11>,
				 <PINMUX_GPIO25__FUNC_DBPI_HSYNC>,
				 <PINMUX_GPIO26__FUNC_DBPI_VSYNC>,
				 <PINMUX_GPIO27__FUNC_DBPI_DE>,
				 <PINMUX_GPIO28__FUNC_DBPI_CK>;
			bias-disable;
			drive-strength = <16>;
		};
	};

	dpi_idle_pins: dpi-idle-pins {
		pins-idle {
			pinmux = <PINMUX_GPIO13__FUNC_GPIO13>,
				 <PINMUX_GPIO14__FUNC_GPIO14>,
				 <PINMUX_GPIO15__FUNC_GPIO15>,
				 <PINMUX_GPIO16__FUNC_GPIO16>,
				 <PINMUX_GPIO17__FUNC_GPIO17>,
				 <PINMUX_GPIO18__FUNC_GPIO18>,
				 <PINMUX_GPIO19__FUNC_GPIO19>,
				 <PINMUX_GPIO20__FUNC_GPIO20>,
				 <PINMUX_GPIO21__FUNC_GPIO21>,
				 <PINMUX_GPIO22__FUNC_GPIO22>,
				 <PINMUX_GPIO23__FUNC_GPIO23>,
				 <PINMUX_GPIO24__FUNC_GPIO24>,
				 <PINMUX_GPIO25__FUNC_GPIO25>,
				 <PINMUX_GPIO26__FUNC_GPIO26>,
				 <PINMUX_GPIO27__FUNC_GPIO27>,
				 <PINMUX_GPIO28__FUNC_GPIO28>;
			output-low;
			bias-disable;
			drive-strength = <16>;
		};
	};
};
